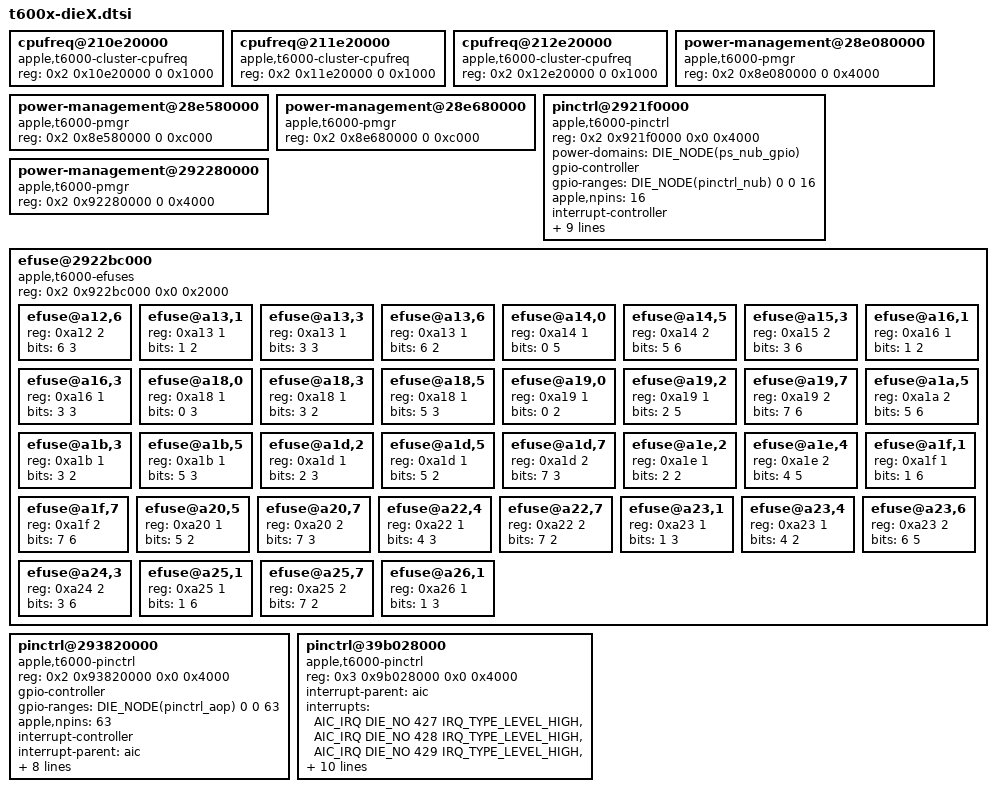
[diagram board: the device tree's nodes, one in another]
// SPDX-License-Identifier: GPL-2.0+ OR MIT
/*
 * Devices used on both dies on the Apple T6002 "M1 Ultra" and present on
 * Apple T6000/T6001 "M1 Pro/Max".
 *
 * Copyright The Asahi Linux Contributors
 */

	DIE_NODE(cpufreq_e): cpufreq@210e20000 {
		compatible = "apple,t6000-cluster-cpufreq", "apple,t8103-cluster-cpufreq", "apple,cluster-cpufreq";
		reg = <0x2 0x10e20000 0 0x1000>;
		#performance-domain-cells = <0>;
	};

	DIE_NODE(cpufreq_p0): cpufreq@211e20000 {
		compatible = "apple,t6000-cluster-cpufreq", "apple,t8103-cluster-cpufreq", "apple,cluster-cpufreq";
		reg = <0x2 0x11e20000 0 0x1000>;
		#performance-domain-cells = <0>;
	};

	DIE_NODE(cpufreq_p1): cpufreq@212e20000 {
		compatible = "apple,t6000-cluster-cpufreq", "apple,t8103-cluster-cpufreq", "apple,cluster-cpufreq";
		reg = <0x2 0x12e20000 0 0x1000>;
		#performance-domain-cells = <0>;
	};

	DIE_NODE(pmgr): power-management@28e080000 {
		compatible = "apple,t6000-pmgr", "apple,pmgr", "syscon", "simple-mfd";
		#address-cells = <1>;
		#size-cells = <1>;
		reg = <0x2 0x8e080000 0 0x4000>;
	};

	DIE_NODE(pmgr_east): power-management@28e580000 {
		compatible = "apple,t6000-pmgr", "apple,pmgr", "syscon", "simple-mfd";
		#address-cells = <1>;
		#size-cells = <1>;
		reg = <0x2 0x8e580000 0 0xc000>;
	};

	DIE_NODE(pmgr_south): power-management@28e680000 {
		compatible = "apple,t6000-pmgr", "apple,pmgr", "syscon", "simple-mfd";
		#address-cells = <1>;
		#size-cells = <1>;
		reg = <0x2 0x8e680000 0 0xc000>;
	};

	DIE_NODE(pinctrl_nub): pinctrl@2921f0000 {
		compatible = "apple,t6000-pinctrl", "apple,pinctrl";
		reg = <0x2 0x921f0000 0x0 0x4000>;
		power-domains = <&DIE_NODE(ps_nub_gpio)>;

		gpio-controller;
		#gpio-cells = <2>;
		gpio-ranges = <&DIE_NODE(pinctrl_nub) 0 0 16>;
		apple,npins = <16>;

		interrupt-controller;
		#interrupt-cells = <2>;
		interrupt-parent = <&aic>;
		interrupts = <AIC_IRQ DIE_NO 623 IRQ_TYPE_LEVEL_HIGH>,
				<AIC_IRQ DIE_NO 624 IRQ_TYPE_LEVEL_HIGH>,
				<AIC_IRQ DIE_NO 625 IRQ_TYPE_LEVEL_HIGH>,
				<AIC_IRQ DIE_NO 626 IRQ_TYPE_LEVEL_HIGH>,
				<AIC_IRQ DIE_NO 627 IRQ_TYPE_LEVEL_HIGH>,
				<AIC_IRQ DIE_NO 628 IRQ_TYPE_LEVEL_HIGH>,
				<AIC_IRQ DIE_NO 629 IRQ_TYPE_LEVEL_HIGH>;
	};

	DIE_NODE(pmgr_mini): power-management@292280000 {
		compatible = "apple,t6000-pmgr", "apple,pmgr", "syscon", "simple-mfd";
		#address-cells = <1>;
		#size-cells = <1>;
		reg = <0x2 0x92280000 0 0x4000>;
	};

	DIE_NODE(efuse): efuse@2922bc000 {
		compatible = "apple,t6000-efuses", "apple,efuses";
		reg = <0x2 0x922bc000 0x0 0x2000>;
		#address-cells = <1>;
		#size-cells = <1>;

		DIE_NODE(atcphy0_auspll_rodco_bias_adjust): efuse@a12,6 {
			reg = <0xa12 2>;
			bits = <6 3>;
		};

		DIE_NODE(atcphy0_auspll_rodco_encap): efuse@a13,1 {
			reg = <0xa13 1>;
			bits = <1 2>;
		};

		DIE_NODE(atcphy0_auspll_dtc_vreg_adjust): efuse@a13,3 {
			reg = <0xa13 1>;
			bits = <3 3>;
		};

		DIE_NODE(atcphy0_auspll_fracn_dll_start_capcode): efuse@a13,6 {
			reg = <0xa13 1>;
			bits = <6 2>;
		};

		DIE_NODE(atcphy0_aus_cmn_shm_vreg_trim): efuse@a14,0 {
			reg = <0xa14 1>;
			bits = <0 5>;
		};

		DIE_NODE(atcphy0_cio3pll_dco_coarsebin0): efuse@a14,5 {
			reg = <0xa14 2>;
			bits = <5 6>;
		};

		DIE_NODE(atcphy0_cio3pll_dco_coarsebin1): efuse@a15,3 {
			reg = <0xa15 2>;
			bits = <3 6>;
		};

		DIE_NODE(atcphy0_cio3pll_dll_start_capcode): efuse@a16,1 {
			reg = <0xa16 1>;
			bits = <1 2>;
		};

		DIE_NODE(atcphy0_cio3pll_dtc_vreg_adjust): efuse@a16,3 {
			reg = <0xa16 1>;
			bits = <3 3>;
		};

		DIE_NODE(atcphy1_auspll_rodco_bias_adjust): efuse@a18,0 {
			reg = <0xa18 1>;
			bits = <0 3>;
		};

		DIE_NODE(atcphy1_auspll_rodco_encap): efuse@a18,3 {
			reg = <0xa18 1>;
			bits = <3 2>;
		};

		DIE_NODE(atcphy1_auspll_dtc_vreg_adjust): efuse@a18,5 {
			reg = <0xa18 1>;
			bits = <5 3>;
		};

		DIE_NODE(atcphy1_auspll_fracn_dll_start_capcode): efuse@a19,0 {
			reg = <0xa19 1>;
			bits = <0 2>;
		};

		DIE_NODE(atcphy1_aus_cmn_shm_vreg_trim): efuse@a19,2 {
			reg = <0xa19 1>;
			bits = <2 5>;
		};

		DIE_NODE(atcphy1_cio3pll_dco_coarsebin0): efuse@a19,7 {
			reg = <0xa19 2>;
			bits = <7 6>;
		};

		DIE_NODE(atcphy1_cio3pll_dco_coarsebin1): efuse@a1a,5 {
			reg = <0xa1a 2>;
			bits = <5 6>;
		};

		DIE_NODE(atcphy1_cio3pll_dll_start_capcode): efuse@a1b,3 {
			reg = <0xa1b 1>;
			bits = <3 2>;
		};

		DIE_NODE(atcphy1_cio3pll_dtc_vreg_adjust): efuse@a1b,5 {
			reg = <0xa1b 1>;
			bits = <5 3>;
		};

		DIE_NODE(atcphy2_auspll_rodco_bias_adjust): efuse@a1d,2 {
			reg = <0xa1d 1>;
			bits = <2 3>;
		};

		DIE_NODE(atcphy2_auspll_rodco_encap): efuse@a1d,5 {
			reg = <0xa1d 1>;
			bits = <5 2>;
		};

		DIE_NODE(atcphy2_auspll_dtc_vreg_adjust): efuse@a1d,7 {
			reg = <0xa1d 2>;
			bits = <7 3>;
		};

		DIE_NODE(atcphy2_auspll_fracn_dll_start_capcode): efuse@a1e,2 {
			reg = <0xa1e 1>;
			bits = <2 2>;
		};

		DIE_NODE(atcphy2_aus_cmn_shm_vreg_trim): efuse@a1e,4 {
			reg = <0xa1e 2>;
			bits = <4 5>;
		};

		DIE_NODE(atcphy2_cio3pll_dco_coarsebin0): efuse@a1f,1 {
			reg = <0xa1f 1>;
			bits = <1 6>;
		};

		DIE_NODE(atcphy2_cio3pll_dco_coarsebin1): efuse@a1f,7 {
			reg = <0xa1f 2>;
			bits = <7 6>;
		};

		DIE_NODE(atcphy2_cio3pll_dll_start_capcode): efuse@a20,5 {
			reg = <0xa20 1>;
			bits = <5 2>;
		};

		DIE_NODE(atcphy2_cio3pll_dtc_vreg_adjust): efuse@a20,7 {
			reg = <0xa20 2>;
			bits = <7 3>;
		};

		DIE_NODE(atcphy3_auspll_rodco_bias_adjust): efuse@a22,4 {
			reg = <0xa22 1>;
			bits = <4 3>;
		};

		DIE_NODE(atcphy3_auspll_rodco_encap): efuse@a22,7 {
			reg = <0xa22 2>;
			bits = <7 2>;
		};

		DIE_NODE(atcphy3_auspll_dtc_vreg_adjust): efuse@a23,1 {
			reg = <0xa23 1>;
			bits = <1 3>;
		};

		DIE_NODE(atcphy3_auspll_fracn_dll_start_capcode): efuse@a23,4 {
			reg = <0xa23 1>;
			bits = <4 2>;
		};

		DIE_NODE(atcphy3_aus_cmn_shm_vreg_trim): efuse@a23,6 {
			reg = <0xa23 2>;
			bits = <6 5>;
		};

		DIE_NODE(atcphy3_cio3pll_dco_coarsebin0): efuse@a24,3 {
			reg = <0xa24 2>;
			bits = <3 6>;
		};

		DIE_NODE(atcphy3_cio3pll_dco_coarsebin1): efuse@a25,1 {
			reg = <0xa25 1>;
			bits = <1 6>;
		};

		DIE_NODE(atcphy3_cio3pll_dll_start_capcode): efuse@a25,7 {
			reg = <0xa25 2>;
			bits = <7 2>;
		};

		DIE_NODE(atcphy3_cio3pll_dtc_vreg_adjust): efuse@a26,1 {
			reg = <0xa26 1>;
			bits = <1 3>;
		};
	};

	DIE_NODE(pinctrl_aop): pinctrl@293820000 {
		compatible = "apple,t6000-pinctrl", "apple,pinctrl";
		reg = <0x2 0x93820000 0x0 0x4000>;

		gpio-controller;
		#gpio-cells = <2>;
		gpio-ranges = <&DIE_NODE(pinctrl_aop) 0 0 63>;
		apple,npins = <63>;

		interrupt-controller;
		#interrupt-cells = <2>;
		interrupt-parent = <&aic>;
		interrupts = <AIC_IRQ DIE_NO 567 IRQ_TYPE_LEVEL_HIGH>,
				<AIC_IRQ DIE_NO 568 IRQ_TYPE_LEVEL_HIGH>,
				<AIC_IRQ DIE_NO 569 IRQ_TYPE_LEVEL_HIGH>,
				<AIC_IRQ DIE_NO 570 IRQ_TYPE_LEVEL_HIGH>,
				<AIC_IRQ DIE_NO 571 IRQ_TYPE_LEVEL_HIGH>,
				<AIC_IRQ DIE_NO 572 IRQ_TYPE_LEVEL_HIGH>,
				<AIC_IRQ DIE_NO 573 IRQ_TYPE_LEVEL_HIGH>;
	};

	DIE_NODE(pinctrl_ap): pinctrl@39b028000 {
		compatible = "apple,t6000-pinctrl", "apple,pinctrl";
		reg = <0x3 0x9b028000 0x0 0x4000>;

		interrupt-parent = <&aic>;
		interrupts = <AIC_IRQ DIE_NO 427 IRQ_TYPE_LEVEL_HIGH>,
				<AIC_IRQ DIE_NO 428 IRQ_TYPE_LEVEL_HIGH>,
				<AIC_IRQ DIE_NO 429 IRQ_TYPE_LEVEL_HIGH>,
				<AIC_IRQ DIE_NO 430 IRQ_TYPE_LEVEL_HIGH>,
				<AIC_IRQ DIE_NO 431 IRQ_TYPE_LEVEL_HIGH>,
				<AIC_IRQ DIE_NO 432 IRQ_TYPE_LEVEL_HIGH>,
				<AIC_IRQ DIE_NO 433 IRQ_TYPE_LEVEL_HIGH>;

		clocks = <&clkref>;
		power-domains = <&DIE_NODE(ps_gpio)>;

		gpio-controller;
		#gpio-cells = <2>;
		gpio-ranges = <&DIE_NODE(pinctrl_ap) 0 0 255>;
		apple,npins = <255>;

		interrupt-controller;
		#interrupt-cells = <2>;
	};
